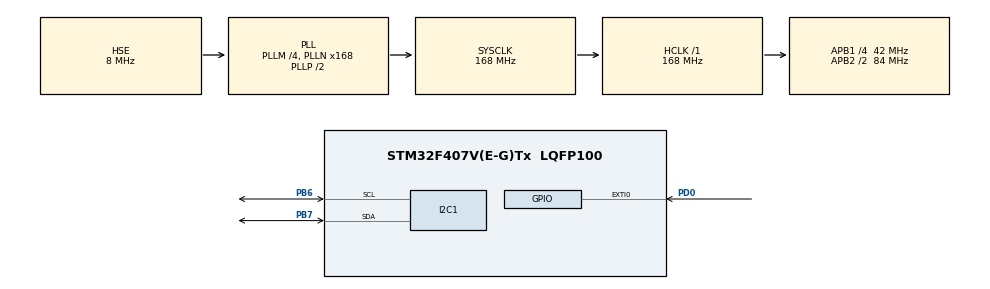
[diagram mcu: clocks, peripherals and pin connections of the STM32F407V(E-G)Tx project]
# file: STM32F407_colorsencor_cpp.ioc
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I2C1.I2C_Mode=I2C_Standard
Mcu.Family=STM32F4
Mcu.Name=STM32F407V(E-G)Tx
Mcu.Package=LQFP100
NVIC.EXTI0_IRQn=true\:0\:0\:false\:false\:true\:true\:true
NVIC.PriorityGroup=NVIC_PRIORITYGROUP_4
NVIC.TIM6_DAC_IRQn=true\:0\:0\:false\:false\:true\:true\:true
PA13.Mode=Trace_Asynchronous_SW
PA13.Signal=SYS_JTMS-SWDIO
PA14.Mode=Trace_Asynchronous_SW
PA14.Signal=SYS_JTCK-SWCLK
PB3.Mode=Trace_Asynchronous_SW
PB3.Signal=SYS_JTDO-SWO
PB6.Mode=I2C
PB6.Signal=I2C1_SCL
PB7.Mode=I2C
PB7.Signal=I2C1_SDA
PD0.Signal=GPXTI0
PH0-OSC_IN.Mode=HSE-External-Oscillator
PH0-OSC_IN.Signal=RCC_OSC_IN
PH1-OSC_OUT.Mode=HSE-External-Oscillator
PH1-OSC_OUT.Signal=RCC_OSC_OUT
ProjectManager.HeapSize=0x200
ProjectManager.StackSize=0x400
ProjectManager.TargetToolchain=STM32CubeIDE
RCC.48MHZClocksFreq_Value=84000000
RCC.AHBFreq_Value=168000000
RCC.APB1CLKDivider=RCC_HCLK_DIV4
RCC.APB1Freq_Value=42000000
RCC.APB1TimFreq_Value=84000000
RCC.APB2CLKDivider=RCC_HCLK_DIV2
RCC.APB2Freq_Value=84000000
RCC.APB2TimFreq_Value=168000000
RCC.CortexFreq_Value=168000000
RCC.HCLKFreq_Value=168000000
RCC.HSE_VALUE=8000000
RCC.HSI_VALUE=16000000
RCC.LSE_VALUE=32768
RCC.PLLM=4
RCC.PLLN=168
RCC.PLLSourceVirtual=RCC_PLLSOURCE_HSE
RCC.SYSCLKFreq_VALUE=168000000
RCC.SYSCLKSource=RCC_SYSCLKSOURCE_PLLCLK
RCC.VCOOutputFreq_Value=336000000
TIM6.AutoReloadPreload=TIM_AUTORELOAD_PRELOAD_ENABLE
TIM6.Period=99
TIM6.Prescaler=1679
TIM6.TIM_MasterOutputTrigger=TIM_TRGO_RESET
VP_TIM6_VS_ClockSourceINT.Mode=Enable_Timer
board=custom

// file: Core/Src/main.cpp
/* USER CODE BEGIN Header */
/**
  ******************************************************************************
  * @file           : main.c
  * @brief          : Main program body
  ******************************************************************************
  * @attention
  *
  * <h2><center>&copy; Copyright (c) 2020 STMicroelectronics.
  * All rights reserved.</center></h2>
  *
  * This software component is licensed by ST under BSD 3-Clause license,
  * the "License"; You may not use this file except in compliance with the
  * License. You may obtain a copy of the License at:
  *                        opensource.org/licenses/BSD-3-Clause
  *
  ******************************************************************************
  */
/* USER CODE END Header */
#include "main.h"
#include "i2c.h"
#include "tim.h"
#include "gpio.h"
#include "Adafruit_TCS34725.h"
#include "stdio.h"

/* USER CODE BEGIN PV */
uint8_t debugStatus=0;
uint8_t state=1;
Adafruit_TCS34725 tcs = Adafruit_TCS34725(TCS34725_INTEGRATIONTIME_700MS, TCS34725_GAIN_1X);
/* USER CODE END PV */

void SystemClock_Config(void);
/* USER CODE BEGIN PFP */
void getRawData_noDelay(uint16_t *r, uint16_t *g, uint16_t *b, uint16_t *c);
/* USER CODE END PFP */

/* USER CODE BEGIN 0 */
/*----------------------------------------------------------------------------*/
/* Private user code ---------------------------------------------------------*/
/*----------------------------------------------------------------------------*/
int _write(int file, char *ptr, int len)
{
    /* Implement your write code here, this is used by puts and printf for example */
    int i=0;
    for(i=0 ; i<len ; i++)
        ITM_SendChar((*ptr++));
    return len;
}
void traceWrite(char *ptr, int len){
    int i=0;
    for(i=0 ; i<len ; i++)
        ITM_SendChar((*ptr++));
    return;
}
/* USER CODE END 0 */

int main(void)
{

  /* MCU Configuration--------------------------------------------------------*/

  /* Reset of all peripherals, Initializes the Flash interface and the Systick. */
  HAL_Init();

  /* Configure the system clock */
  SystemClock_Config();

  /* Initialize all configured peripherals */
  MX_GPIO_Init();
  MX_I2C1_Init();
  MX_TIM6_Init();
  /* USER CODE BEGIN 2 */

  /* Initialise with specific int time and gain values */
  if (tcs.begin()) {
      debugStatus=0x55; //Found sensor
  } else {
      debugStatus=0xAA;    //No TCS34725 found ... check your connections
    while (1);
  }
  // Set persistence filter to generate an interrupt for every RGB Cycle, regardless of the integration limits
  tcs.write8(TCS34725_PERS, TCS34725_PERS_NONE);
  tcs.setInterrupt(true);
  //ITM_SendChar( 65 );   //  Send ASCII code 65 = ’A’
  int clock = SystemCoreClock;
  char txt[20]={0};
  snprintf(txt,20,"clock= %d\n",clock);
  traceWrite(txt,20);
  /* USER CODE END 2 */

  /* Infinite loop */
  /* USER CODE BEGIN WHILE */
  while (1)
  {

      if (state==1) {
          state = 0;
          uint16_t r, g, b, c, colorTemp, lux;
          getRawData_noDelay(&r, &g, &b, &c);
          colorTemp = tcs.calculateColorTemperature(r, g, b);
          lux = tcs.calculateLux(r, g, b);
          char txt[80]={0};
          snprintf(txt,80,"Color Temp: %dK LUX: %d R: %d G: %d B: %d C: %d\n",colorTemp,lux,r,g,b,c);
          traceWrite(txt,80);

          tcs.clearInterrupt();
      }
      HAL_Delay(1000);

      /* USER CODE END WHILE */

  }
}

void SystemClock_Config(void)
{
  RCC_OscInitTypeDef RCC_OscInitStruct = {0};
  RCC_ClkInitTypeDef RCC_ClkInitStruct = {0};

  /** Configure the main internal regulator output voltage
  */
  __HAL_RCC_PWR_CLK_ENABLE();
  __HAL_PWR_VOLTAGESCALING_CONFIG(PWR_REGULATOR_VOLTAGE_SCALE1);
  /** Initializes the RCC Oscillators according to the specified parameters
  * in the RCC_OscInitTypeDef structure.
  */
  RCC_OscInitStruct.OscillatorType = RCC_OSCILLATORTYPE_HSE;
  RCC_OscInitStruct.HSEState = RCC_HSE_ON;
  RCC_OscInitStruct.PLL.PLLState = RCC_PLL_ON;
  RCC_OscInitStruct.PLL.PLLSource = RCC_PLLSOURCE_HSE;
  RCC_OscInitStruct.PLL.PLLM = 4;
  RCC_OscInitStruct.PLL.PLLN = 168;
  RCC_OscInitStruct.PLL.PLLP = RCC_PLLP_DIV2;
  RCC_OscInitStruct.PLL.PLLQ = 4;
  if (HAL_RCC_OscConfig(&RCC_OscInitStruct) != HAL_OK)
  {
    Error_Handler();
  }
  /** Initializes the CPU, AHB and APB buses clocks
  */
  RCC_ClkInitStruct.ClockType = RCC_CLOCKTYPE_HCLK|RCC_CLOCKTYPE_SYSCLK
                              |RCC_CLOCKTYPE_PCLK1|RCC_CLOCKTYPE_PCLK2;
  RCC_ClkInitStruct.SYSCLKSource = RCC_SYSCLKSOURCE_PLLCLK;
  RCC_ClkInitStruct.AHBCLKDivider = RCC_SYSCLK_DIV1;
  RCC_ClkInitStruct.APB1CLKDivider = RCC_HCLK_DIV4;
  RCC_ClkInitStruct.APB2CLKDivider = RCC_HCLK_DIV2;

  if (HAL_RCC_ClockConfig(&RCC_ClkInitStruct, FLASH_LATENCY_5) != HAL_OK)
  {
    Error_Handler();
  }
}

/* USER CODE BEGIN 4 */

/* tcs.getRawData() does a delay(Integration_Time) after the sensor readout.
We don't need to wait for the next integration cycle because we receive an interrupt when the integration cycle is complete*/
void getRawData_noDelay(uint16_t *r, uint16_t *g, uint16_t *b, uint16_t *c)
{
  *c = tcs.read16(TCS34725_CDATAL);
  *r = tcs.read16(TCS34725_RDATAL);
  *g = tcs.read16(TCS34725_GDATAL);
  *b = tcs.read16(TCS34725_BDATAL);
}

//===================================================
//== EXT0 IRQ CallBack                             ==
//===================================================

void HAL_GPIO_EXTI_Callback(uint16_t GPIO_Pin){
    if (GPIO_Pin==1) state = 1;
}

/* USER CODE END 4 */

void Error_Handler(void)
{
}

/************************ (C) COPYRIGHT STMicroelectronics *****END OF FILE****/
